# ATmega328PB device description
Architecture: AVR8; Family: megaAVR
Registers are 8-bit, access not given, no defined reset value unless marked. A register's access mark holds for its fields unless they carry their own. Offsets are from the block's base; [hi:lo] are bit positions.

## LOCKBIT — Lockbits
Instances: LOCKBIT 0 in lockbits
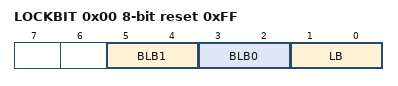
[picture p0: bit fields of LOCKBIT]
0x00 LOCKBIT reset 0xFF
  [5:4] BLB1 — Boot Loader Protection Mode
    0=LPM_SPM_DISABLE (LPM and SPM prohibited in Boot Section); 1=LPM_DISABLE (LPM prohibited in Boot Section); 2=SPM_DISABLE (SPM prohibited in Boot Section); 3=NO_LOCK (No lock on SPM and LPM in Boot Section)
  [3:2] BLB0 — Boot Loader Protection Mode
    0=LPM_SPM_DISABLE (LPM and SPM prohibited in Application Section); 1=LPM_DISABLE (LPM prohibited in Application Section); 2=SPM_DISABLE (SPM prohibited in Application Section); 3=NO_LOCK (No lock on SPM and LPM in Application Section)
  [1:0] LB — Memory Lock
    0=PROG_VER_DISABLED (Further programming and verification disabled); 2=PROG_DISABLED (Further programming disabled); 3=NO_LOCK (No memory lock features enabled)

## USART0 — USART
Instances: USART0 0x00
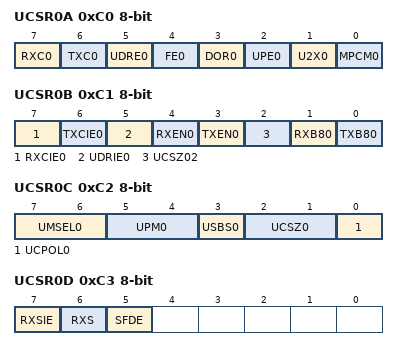
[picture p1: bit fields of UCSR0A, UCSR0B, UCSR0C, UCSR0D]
0xC0 UCSR0A — USART Control and Status Register A
  [7] RXC0 ro — USART Receive Complete
  [6] TXC0 — USART Transmit Complete
  [5] UDRE0 ro — USART Data Register Empty
  [4] FE0 ro — Framing Error
  [3] DOR0 ro — Data overRun
  [2] UPE0 ro — Parity Error
  [1] U2X0 — Double the USART transmission speed
  [0] MPCM0 — Multi-processor Communication Mode
0xC1 UCSR0B — USART Control and Status Register B
  [7] RXCIE0 — RX Complete Interrupt Enable
  [6] TXCIE0 — TX Complete Interrupt Enable
  [5] UDRIE0 — USART Data register Empty Interrupt Enable
  [4] RXEN0 — Receiver Enable
  [3] TXEN0 — Transmitter Enable
  [2] UCSZ02 — Character Size - together with UCSZ0 in UCSR0C
  [1] RXB80 — Receive Data Bit 8
  [0] TXB80 — Transmit Data Bit 8
0xC2 UCSR0C — USART Control and Status Register C
  [7:6] UMSEL0 — USART Mode Select
    0=ASYNCHRONOUS_USART; 1=SYNCHRONOUS_USART; 3=MASTER_SPI
  [5:4] UPM0 — Parity Mode Bits
    0=DISABLED; 2=ENABLED_EVEN_PARITY; 3=ENABLED_ODD_PARITY
  [3] USBS0 — Stop Bit Select
    0=1_BIT; 1=2_BIT
  [2:1] UCSZ0 — Character Size - together with UCSZ2 in UCSR0B
  [0] UCPOL0 — Clock Polarity
0xC3 UCSR0D — USART Control and Status Register D
  [7] RXSIE — USART RX Start Interrupt Enable
  [6] RXS — USART RX Start
  [5] SFDE — Start frame detection enable
0xC4 UBRR0 16-bit bits used 11:0 — USART Baud Rate Register Bytes
0xC6 UDR0 — USART I/O Data Register 0

## USART1 — USART
Instances: USART1 0x00
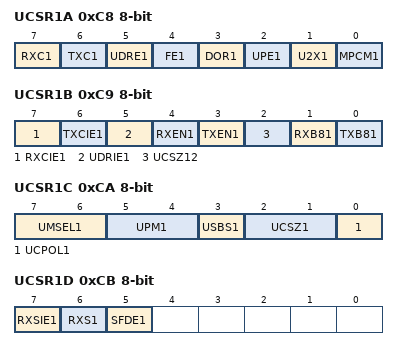
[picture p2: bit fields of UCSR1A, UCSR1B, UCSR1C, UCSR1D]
0xC8 UCSR1A — USART Control and Status Register A
  [7] RXC1 — USART Receive Complete
  [6] TXC1 — USART Transmit Complete
  [5] UDRE1 — USART Data Register Empty
  [4] FE1 — Framing Error
  [3] DOR1 — Data overRun
  [2] UPE1 — Parity Error
  [1] U2X1 — Double the USART transmission speed
  [0] MPCM1 — Multi-processor Communication Mode
0xC9 UCSR1B — USART Control and Status Register B
  [7] RXCIE1 — RX Complete Interrupt Enable
  [6] TXCIE1 — TX Complete Interrupt Enable
  [5] UDRIE1 — USART Data register Empty Interrupt Enable
  [4] RXEN1 — Receiver Enable
  [3] TXEN1 — Transmitter Enable
  [2] UCSZ12 — Character Size - together with UCSZ0 in UCSR1C
  [1] RXB81 — Receive Data Bit 8
  [0] TXB81 — Transmit Data Bit 8
0xCA UCSR1C — USART Control and Status Register C
  [7:6] UMSEL1 — USART Mode Select
    0=ASYNCHRONOUS_USART; 1=SYNCHRONOUS_USART; 3=MASTER_SPI
  [5:4] UPM1 — Parity Mode Bits
    0=DISABLED; 2=ENABLED_EVEN_PARITY; 3=ENABLED_ODD_PARITY
  [3] USBS1 — Stop Bit Select
    0=1_BIT; 1=2_BIT
  [2:1] UCSZ1 — Character Size - together with UCSZ12 in UCSR1B
  [0] UCPOL1 — Clock Polarity
0xCB UCSR1D — USART Control and Status Register D
  [7] RXSIE1 — USART RX Start Interrupt Enable
  [6] RXS1 — USART RX Start
  [5] SFDE1 — Start frame detection enable
0xCC UBRR1 16-bit bits used 11:0 — USART Baud Rate Register Bytes
0xCE UDR1 — USART I/O Data Register
